# CY8C5868AXI_LP035 register map
File version: 0.1
CY8C58LP
Registers are 8-bit, read-write, no defined reset value unless marked. A register's access mark holds for its fields unless they carry their own. Offsets are from the block's base; lines under a group give offsets from that group; [hi:lo] are bit positions; {n}, {i} and the like mark numbered series; 'fields as' and 'values as' point back to an identical list; <NAME> marks a mode.

## Memory map
0x00000000 KeyNote_Low
0x00000000 DACBuffer
0x00000000 Wave_Out_VDAC8
0x00000000 KeyNote_High
0x00000000 Waveform_Send

## KeyNote_Low
Base 0x00000000
0x40006466 KeyNote_Low_STATUS_REG
0x40006486 KeyNote_Low_MASK_REG
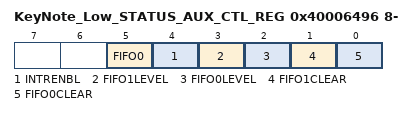
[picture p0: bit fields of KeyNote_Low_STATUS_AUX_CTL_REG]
0x40006496 KeyNote_Low_STATUS_AUX_CTL_REG
  [5] FIFO0 — FIFO0 clear
    1=ENABLED (Enable counter); 0=DISABLED (Disable counter)
  [4] INTRENBL — Enables or disables the Interrupt
    1=ENABLED (Interrupt enabled); 0=DISABLED (Interrupt disabled)
  [3] FIFO1LEVEL — FIFO level
    1=ENABLED (FIFO LVL: input mode: FIFO at least 1/2 empty; output mode: FIFO at least 1/2 full); 0=DISABLED (FIFO LVL: input mode: FIFO not full; output mode: FIFO not empty)
  [2] FIFO0LEVEL — FIFO level
    values as FIFO1LEVEL
  [1] FIFO1CLEAR — FIFO clear
    1=ENABLED (Clear FIFO state); 0=DISABLED (Normal FIFO operation)
  [0] FIFO0CLEAR — FIFO clear
    values as FIFO1CLEAR

## DACBuffer
Base 0x00000000
0x400043A4 PM_ACT_CFG4 — Active Power Mode Configuration Register 4
  [3:0] EN_OPAMP — Enables subsystems during active power mode
    0=Blk_0 (Enables analog linear output buffer for Opamp block 0); 2=Blk_1 (Enables analog linear output buffer for Opamp block 1); 4=Blk_2 (Enables analog linear output buffer for Opamp block 2); 8=Blk_3 (Enables analog linear output buffer for Opamp block 3)
0x400043B4 PM_STBY_CFG4 — Standby Power Mode Configuration Register 4
  [3:0] EN_OPAMP — Enables subsystems during standby power mode
    values as PM_ACT_CFG4.EN_OPAMP
0x40004620 OPAMP__TR0 — Analog Output Buffer Trim Register 0
  [4:0] offset_trim — Offset Trim: 420uV typical step size; +/- 6.8mV offset trimmable range
0x40004621 OPAMP__TR1 — Analog Output Buffer Trim Register 1
0x40005858 OPAMP__CR — Analog Output Buffer Configuration Register
  [1:0] pwr_mode — Power Mode
    0=Default_Fast (Default Power mode Fast); 1=Slow (Power Mode Slow); 2=Medium (Power Mode Medium); 3=Fast (Power Mode Fast)
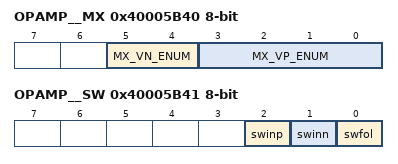
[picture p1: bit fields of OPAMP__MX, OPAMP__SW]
0x40005B40 OPAMP__MX — Analog Buffer Input Selection Register
  [5:4] MX_VN_ENUM — MUX select VN (Negative terminal input)
    0=OPAMP0_MX_VN_DEFAULT (Default - Not Connected (NC)); 1=OPAMP0_MX_VN_AG4 (MUX Selection AGL(4)); 2=OPAMP0_MX_VN_AG6 (MUX Selection AGL(6)); 3=OPAMP0_MX_VN_0x3 (Reserved (NC))
  [3:0] MX_VP_ENUM — MUX select VP (Positive terminal input)
    0=OPAMP0_MX_VP_DEFAULT (Default - Not Connected (NC)); {v}=OPAMP0_MX_VP_AG{v+3} (MUX Selection AGL({v+3})) (v=1..4); {v}=OPAMP0_MX_VP_ABUS{v-5} (MUX Selection ABUSL({v-5})) (v=5..8); 9=OPAMP0_MX_VP_VREF (MUX Selection: OPAMP Voltage Reference); {v}=OPAMP0_MX_VP_H_{0x0+v} (Reserved (NC)) (v=10..15)
0x40005B41 OPAMP__SW — Analog Buffer Routing Switch Register
  [2] swinp — Switch Enable Positive Input
  [1] swinn — Switch Enable Negative Input
  [0] swfol — Switch Enable Follow

## Wave_Out_VDAC8
Base 0x00000000
0x400043A8 VDAC8_PM_ACT_CFG — Active Power Mode Configuration Register 8
  [4:0] en_dac — Enable DAC block(s). Populated subsystems are counted from the LSB
0x400043B8 VDAC8_PM_STBY_CFG — Standby Power Mode Configuration Register 8
  fields as VDAC8_PM_ACT_CFG
0x4000460A VDAC8_TR
  [7:0] tr — 8 Calibration bits
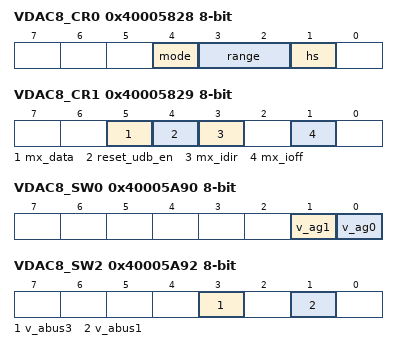
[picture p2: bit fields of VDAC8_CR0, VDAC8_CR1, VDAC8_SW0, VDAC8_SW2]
0x40005828 VDAC8_CR0 — DAC Block Control Register 0
  [4] mode ro — Mode Bit
    0=DAC_MODE_V (voltage DAC); 1=DAC_MODE_I (current DAC)
  [3:2] range — Ranges for mode=0 (VDAC) and mode=1 (IDAC)
    0=DAC_RANGE_0 (x0=0V to 4*vref (1.024V); 0 to 31.875uA); 1=DAC_RANGE_1 (x1=0V to 16*vref (4.096V); 0 to 255uA); 2=DAC_RANGE_2 (x0=0V to 4*vref (1.024V); 0 to 2.040mA); 3=DAC_RANGE_3 (x1=0V to 16*vref (4.096V); not used)
  [1] hs — High Speed Bit
    0=DAC_HS_LOWPOWER (regular (low power)); 1=DAC_HS_HIGHSPEED (high speed (higher power))
0x40005829 VDAC8_CR1 — DAC Block Control Register 1
  [5] mx_data — Select DATA source
    0=MX_DATA_REG (Select register source (DACxn_D)); 1=MX_DATA_UDB (Select UDB source)
  [4] reset_udb_en — DAC reset enable
    0=RESET_UDB_EN_DISABLE (Disable DAC Reset Source from UDB (System reset always resets)); 1=RESET_UDB_EN_ENABLE (Enable DAC Reset Source from UDB)
  [3] mx_idir — Mux selection for DAC current direction control
    0=MX_IDIR_REG (Register source idirbit selected); 1=MX_IDIR_UDB (UDB ictrl selected)
  [1] mx_ioff — Mux selection for DAC current off control
    0=MX_IOFF_REG (Register source ioffbit selected); 1=MX_IOFF_UDB (UDB ictrl selected)
0x40005A90 VDAC8_SW0 — DAC Analog Routing Register 0
  [1] v_ag1 — Connect voltage output to analog global of same side
    0=AG_NC (not connected); 1=AG_CONNECTED (Connect to Analog Global)
  [0] v_ag0 — Connect voltage output to analog global of same side
    values as v_ag1
0x40005A92 VDAC8_SW2 — DAC Analog Routing Register 2
  [3] v_abus3 — Connect voltage output to analog (local) bus of the same side
    0=ABUS_NC (not connected); 1=ABUS_CONNECTED (Connect to Analog (local) Bus)
  [1] v_abus1 — Connect voltage output to analog (local) bus of the same side
    values as v_abus3
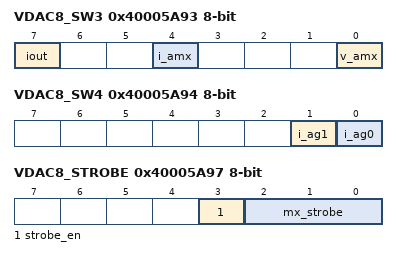
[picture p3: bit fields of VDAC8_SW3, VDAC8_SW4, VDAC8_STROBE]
0x40005A93 VDAC8_SW3 — DAC Analog Routing Register 3
  [7] iout — Connect current output to pad
    0=IOUT_NC (not connected); 1=IOUT_CONNECT (Connect to pad)
  [4] i_amx — Connect current output to Analog Mux Bus
    0=AMX_NC (not connected); 1=AMX_CONNECTED (Connect to AMUXBUS)
  [0] v_amx — Connect voltage output to Analog Mux Bus
    values as i_amx
0x40005A94 VDAC8_SW4 — DAC Analog Routing Register 4
  [1] i_ag1 — Connect current output to analog global of same side
    values as VDAC8_SW0.v_ag1
  [0] i_ag0 — Connect current output to analog global of same side
    values as VDAC8_SW0.v_ag1
0x40005A97 VDAC8_STROBE — DAC Strobe Register
  [3] strobe_en — Strobe gating control (See mx_strobe==3'h0)
    0=disable strobe; 1=enable strobe
  [2:0] mx_strobe — Strobe source selection
    0=MX_STROBE_BUSWRITE (Select bus write strobe source (Enable gater regardless of strobe_en setting)); 1=MX_STROBE_UDB_SRC (Select UDB strobe source); 2=MX_STROBE_NC_2 (NC); 3=MX_STROBE_NC_3 (NC); {v}=MX_STROBE_CLK_A{v-4}_DIG (Select clk_a{v-4}_dig) (v=4..7)
0x40005B82 VDAC8_DATA — DAC Data Register
  [7:0] data — 8 DAC Data bits

## KeyNote_High
Base 0x00000000
0x40006564 KeyNote_High_STATUS_REG
0x40006584 KeyNote_High_MASK_REG
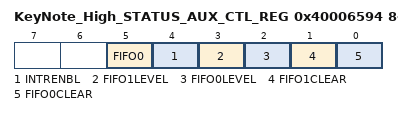
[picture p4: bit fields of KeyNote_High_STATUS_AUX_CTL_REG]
0x40006594 KeyNote_High_STATUS_AUX_CTL_REG
  fields as KeyNote_Low.KeyNote_Low_STATUS_AUX_CTL_REG

## Waveform_Send
Base 0x00000000
0x400043A3 Waveform_Send_GLOBAL_ENABLE — PM.ACT.CFG
  [3:0] en_timer — Enable timer/counters.
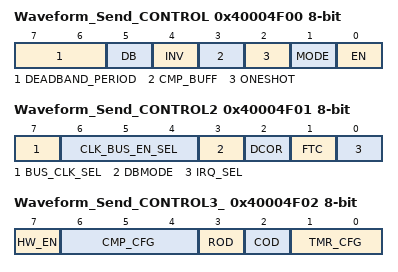
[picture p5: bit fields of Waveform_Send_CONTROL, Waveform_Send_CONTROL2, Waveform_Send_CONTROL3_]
0x40004F00 Waveform_Send_CONTROL — TMRx.CFG0
  [7:6] DEADBAND_PERIOD
  [5] DB — Deadband mode--Deadband phases phi1 and phi2 are outputted on CMP and TC output pins respectively.
    0=Timer (CMP and TC are output.); 1=Deadband (PHI1 (instead of CMP) and PHI2 (instead of TC) are output.)
  [4] INV — Invert sense of TIMEREN signal
  [3] CMP_BUFF — Buffer compare register. Compare register updates only on timer terminal count.
  [2] ONESHOT — Timer stops upon reaching stop condition defined by TMR_CFG bits. Can be restarted by asserting TIMER RESET or disabling and re-enabling block.
  [1] MODE — Mode. (0 = Timer; 1 = Comparator)
    0=Timer mode. CNT/CMP register holds timer count value.; 1=Comparator mode. CNT/CMP register holds comparator threshold value.
  [0] EN — Enables timer/comparator.
0x40004F01 Waveform_Send_CONTROL2 — TMRx.CFG1
  [7] BUS_CLK_SEL — Bus Clock selection.
  [6:4] CLK_BUS_EN_SEL — Digital Global Clock selection.
  [3] DBMODE — Deadband mode (asynchronous/synchronous). CMP output pin is also affected when not in deadband mode (CFG0.DEADBAND).
  [2] DCOR — Disable Clear on Read (DCOR) of Status Register SR0.
  [1] FTC — First Terminal Count (FTC). Setting this bit forces a single pulse on the TC pin when first enabled.
    0=Disable_FTC (Disable the single cycle pulse, which signifies the timer is starting.); 1=Enable_FTC (Enable the single cycle pulse, which signifies the timer is starting.)
  [0] IRQ_SEL — Irq selection. (0 = raw interrupts; 1 = status register interrupts)
0x40004F02 Waveform_Send_CONTROL3_ — TMRx.CFG2
  [7] HW_EN — When set Timer Enable controls counting.
  [6:4] CMP_CFG — Comparator configurations
    0=Equal (Compare Equal); 1=Less_than (Compare Less Than); 2=Less_than_or_equal (Compare Less Than or Equal .); 3=Greater (Compare Greater Than .); 4=Greater_than_or_equal (Compare Greater Than or Equal)
  [3] ROD — Reset On Disable (ROD). Resets internal state of output logic
  [2] COD — Clear On Disable (COD). Clears or gates outputs to zero.
  [1:0] TMR_CFG — Timer configuration (MODE = 0): 000 = Continuous; 001 = Pulsewidth; 010 = Period; 011 = Stop on IRQ
    0=Continuous (Timer runs while EN bit of CFG0 register is set to '1'.); 1=Pulsewidth (Timer runs from positive to negative edge of TIMEREN.); 2=Period (Timer runs from positive to positive edge of TIMEREN.); 3=Irq (Timer runs until IRQ.)
0x40004F04 Waveform_Send_PERIOD 16-bit — TMRx.PER0 - Assigned Period
0x40004F06 Waveform_Send_COUNTER 16-bit — TMRx.CNT_CMP0 - Current Down Counter Value
